# sample register map
Vendor: nodamushi; Series: nodamushi test; File version: 1.0
Sample SVD for test
CPU: CM4 r1p0, little endian, MPU, no FPU, 3 interrupt priority bits
Registers are 32-bit, read-write, reset 0x0 unless marked. A register's access mark holds for its fields unless they carry their own. Offsets are from the block's base; lines under a group give offsets from that group; [hi:lo] are bit positions; {n}, {i} and the like mark numbered series; 'fields as' and 'values as' point back to an identical list; <NAME> marks a mode.

## Memory map
0x40010000 TIMER0 size 0x100 — timer
0x40010100 TIMER1 size 0x100
0x40010200 TIMER2 size 0x100

## Interrupts
0 TIMER0 — Timer 0 interrupt
4 TIMER1 — Timer 2 interrupt
6 TIMER2 — Timer 2 interrupt

## TIMER0 — timer
Base 0x40010000
Same registers: TIMER1 0x40010100
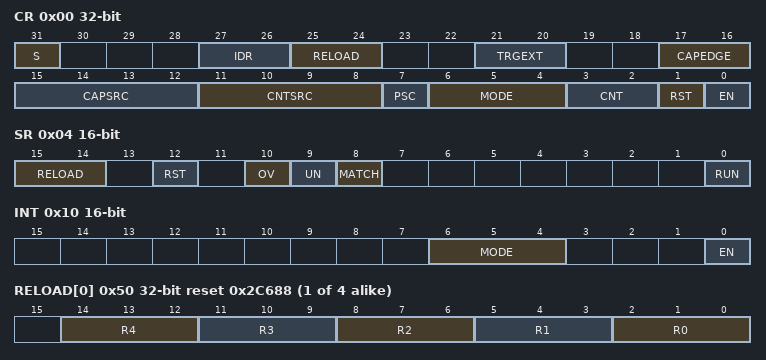
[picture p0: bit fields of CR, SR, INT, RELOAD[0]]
0x00 CR rw-once (reset mask 0x1337F7F) — Control Register
  [31] S rw — Starts and Stops the Timer / Counter
    0=STOP (Timer / Counter is stopped); 1=START (Timer / Counter is started)
  [27:26] IDR rw — Selects, if Reload Register number is incremented, decremented or not modified
    0=KEEP (Reload Register number does not change automatically); 1=INCREMENT (Reload Register number is incremented on each match); 2=DECREMENT (Reload Register number is decremented on each match)
  [25:24] RELOAD rw — Select RELOAD Register n to reload Timer on condition
    {v}=Selects Reload Register number {v} (v=0..3)
  [21:20] TRGEXT rw — Triggers an other Peripheral
    0=NONE (No Trigger is emitted); 1=DMA1 (DMA Controller 1 is triggered, dependant on MODE); 2=DMA2 (DMA Controller 2 is triggered, dependant on MODE); 3=UART (UART is triggered, dependant on MODE)
  [17:16] CAPEDGE rw — Capture Edge, select which Edge should result in a counter increment or decrement
    0=RISING (Only rising edges result in a counter increment or decrement); 1=FALLING (Only falling edges result in a counter increment or decrement); 2=BOTH (Rising and falling edges result in a counter increment or decrement)
  [15:12] CAPSRC rw — Timer / Counter Capture Source
    0=CClk (Core Clock); {v}=GPIOA_{v-1} (GPIO A, PIN {v-1}) (v=1..8); {v}=GPIOB_{v-9} (GPIO B, PIN {v-9}) (v=9..12); 13=GPIOC_0 (GPIO C, PIN 0); 14=GPIOC_5 (GPIO C, PIN 1); 15=GPIOC_6 (GPIO C, PIN 2)
  [11:8] CNTSRC rw — Timer / Counter Source Divider
    0=CAP_SRC (Capture Source is used directly); 1=CAP_SRC_div2 (Capture Source is divided by 2); 2=CAP_SRC_div4 (Capture Source is divided by 4); 3=CAP_SRC_div8 (Capture Source is divided by 8); 4=CAP_SRC_div16 (Capture Source is divided by 16); 5=CAP_SRC_div32 (Capture Source is divided by 32); 6=CAP_SRC_div64 (Capture Source is divided by 64); 7=CAP_SRC_div128 (Capture Source is divided by 128); 8=CAP_SRC_div256 (Capture Source is divided by 256)
  [7] PSC rw — Use Prescaler
    0=Disabled (Prescaler is not used); 1=Enabled (Prescaler is used as divider)
  [6:4] MODE rw — Operation Mode
    0=Continous (Timer runs continously); 1=Single_ZERO_MAX (Timer counts to 0x00 or 0xFFFFFFFF (depending on CNT) and stops); 2=Single_MATCH (Timer counts to the Value of MATCH Register and stops); 3=Reload_ZERO_MAX (Timer counts to 0x00 or 0xFFFFFFFF (depending on CNT), loads the RELOAD Value and continues); 4=Reload_MATCH (Timer counts to the Value of MATCH Register, loads the RELOAD Value and continues)
  [3:2] CNT write-once — Counting direction
    0=C0; 1=C1; 2=C2
  [1] RST wo — Reset Timer
    0=No_Action (Write as ZERO if necessary); 1=Reset_Timer (Reset the Timer)
  [0] EN ro — Enable
    0=Disable (Timer is disabled and does not operate); 1=Enable (Timer is enabled and can operate)
0x04 SR 16-bit — Status Register
  [15:14] RELOAD ro — Shows the currently active RELOAD Register
    {v}=Reload Register number {v} is active (v=0..3)
  [12] RST ro — Shows if Timer is in RESET state
    0=Ready (Timer is not in RESET state and can operate); 1=In_Reset (Timer is in RESET state and can not operate)
  [10] OV — Shows if an overflow occured. This flag is sticky
    0=No overflow occured since last clear; 1=Overflow_occured (A minimum of one overflow occured since last clear)
  [9] UN — Shows if an underflow occured. This flag is sticky
    0=No underflow occured since last clear; 1=Underflow (A minimum of one underflow occured since last clear)
  [8] MATCH — Shows if the MATCH was hit
    0=No_Match (The MATCH condition was not hit); 1=Match_Hit (The MATCH condition was hit)
  [0] RUN ro — Shows if Timer is running or not
    0=Stopped (Timer is not running); 1=Running (Timer is running)
0x10 INT 16-bit — Interrupt Register
  [6:4] MODE — Interrupt Mode, selects on which condition the Timer should generate an Interrupt
    0=Match (Timer generates an Interrupt when the MATCH condition is hit); 1=Underflow (Timer generates an Interrupt when it underflows); 2=Overflow (Timer generates an Interrupt when it overflows)
  [0] EN — Interrupt Enable
    0=Disabled (Timer does not generate Interrupts); 1=Enable (Timer triggers the TIMERn Interrupt)
0x20 COUNT — The Counter Register reflects the actual Value of the Timer/Counter
0x24 MATCH — The Match Register stores the compare Value for the MATCH condition
0x28 PRESCALE_RD ro — The Prescale Register stores the Value for the prescaler. The cont event gets divided by this value
0x28 PRESCALE_WR wo — The Prescale Register stores the Value for the prescaler. The cont event gets divided by this value
{0x50+4i} RELOAD[{i}] (i=0..3) rw-once reset 0x2C688
  [3n+2:3n] R{n} (n=0..4)

## TIMER2
Base 0x40010200
Registers as TIMER0; these are added or differ:
{0x60+4i} FOO{i}BAR (i=0..3)
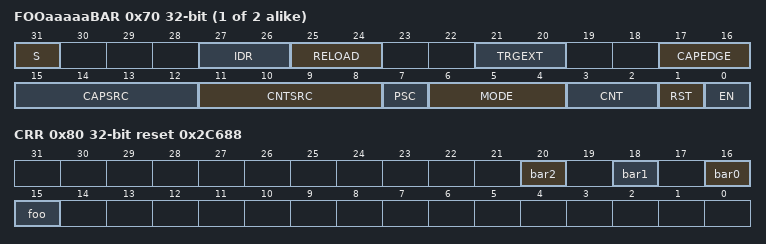
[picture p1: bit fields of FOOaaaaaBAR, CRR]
0x70 FOO{x}BAR (x=aaaaa,100-103; step 0x4) (reset mask 0x1337F7F) — Control Register
  [31] S — Starts and Stops the Timer / Counter
    0=STOP (Timer / Counter is stopped); 1=START (Timer / Counter is started)
  [27:26] IDR — Selects, if Reload Register number is incremented, decremented or not modified
    0=KEEP (Reload Register number does not change automatically); 1=INCREMENT (Reload Register number is incremented on each match); 2=DECREMENT (Reload Register number is decremented on each match)
  [25:24] RELOAD — Select RELOAD Register n to reload Timer on condition
    {v}=Selects Reload Register number {v} (v=0..3)
  [21:20] TRGEXT — Triggers an other Peripheral
    0=NONE (No Trigger is emitted); 1=DMA1 (DMA Controller 1 is triggered, dependant on MODE); 2=DMA2 (DMA Controller 2 is triggered, dependant on MODE); 3=UART (UART is triggered, dependant on MODE)
  [17:16] CAPEDGE — Capture Edge, select which Edge should result in a counter increment or decrement
    values as TIMER0.CR.CAPEDGE
  [15:12] CAPSRC — Timer / Counter Capture Source
    0=CClk (Core Clock); {v}=GPIOA_{v-1} (GPIO A, PIN {v-1}) (v=1..8); {v}=GPIOB_{v-9} (GPIO B, PIN {v-9}) (v=9..12); 13=GPIOC_0 (GPIO C, PIN 0); 14=GPIOC_5 (GPIO C, PIN 1); 15=GPIOC_6 (GPIO C, PIN 2)
  [11:8] CNTSRC — Timer / Counter Source Divider
    values as TIMER0.CR.CNTSRC
  [7] PSC — Use Prescaler
    0=Disabled (Prescaler is not used); 1=Enabled (Prescaler is used as divider)
  [6:4] MODE — Operation Mode
    values as TIMER0.CR.MODE
  [3:2] CNT write-once — Counting direction
    0=C0; 1=C1; 2=C2
  [1] RST wo — Reset Timer
    0=No_Action (Write as ZERO if necessary); 1=Reset_Timer (Reset the Timer)
  [0] EN ro — Enable
    0=Disable (Timer is disabled and does not operate); 1=Enable (Timer is enabled and can operate)
0x80 CRR rw-once reset 0x2C688
  [2n+16] bar{n} (n=0..2), [15] foo

## Licence text in the file
This example is a modification of the CMSIS5 SVD sample. (.A.)
